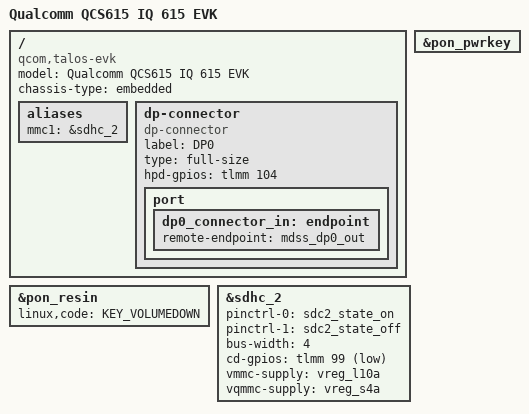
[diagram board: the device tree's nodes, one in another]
// SPDX-License-Identifier: BSD-3-Clause
/*
 * Copyright (c) Qualcomm Technologies, Inc. and/or its subsidiaries.
 */
/dts-v1/;

#include "talos-evk-som.dtsi"

/ {
	model = "Qualcomm QCS615 IQ 615 EVK";
	compatible = "qcom,talos-evk", "qcom,qcs615", "qcom,sm6150";
	chassis-type = "embedded";

	aliases {
		mmc1 = &sdhc_2;
	};

	dp-connector {
		compatible = "dp-connector";
		label = "DP0";
		type = "full-size";

		hpd-gpios = <&tlmm 104 GPIO_ACTIVE_HIGH>;

		port {
			dp0_connector_in: endpoint {
				remote-endpoint = <&mdss_dp0_out>;
			};
		};
	};
};

&pon_pwrkey {
	status = "okay";
};

&pon_resin {
	linux,code = <KEY_VOLUMEDOWN>;

	status = "okay";
};

&sdhc_2 {
	pinctrl-0 = <&sdc2_state_on>;
	pinctrl-1 = <&sdc2_state_off>;
	pinctrl-names = "default", "sleep";

	bus-width = <4>;
	cd-gpios = <&tlmm 99 GPIO_ACTIVE_LOW>;

	vmmc-supply = <&vreg_l10a>;
	vqmmc-supply = <&vreg_s4a>;

	status = "okay";
};
